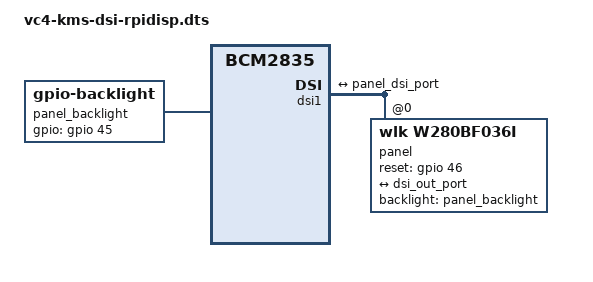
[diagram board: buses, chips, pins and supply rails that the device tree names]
/dts-v1/;
/plugin/;
/ {
	compatible = "brcm,bcm2835";  

	fragment@0 {
		target-path="/";
		__overlay__ {
			panel_backlight: panel_backlight {
				compatible = "gpio-backlight";
				gpios = <&gpio 45 0>;
				default-on;
			};
		};
	};
	
	fragment@1 {
		target = <&dsi1>;
		__overlay__{
			status = "okay";
			#address-cells = <1>;
			#size-cells = <0>;
			port {
				dsi_out_port:endpoint {
					remote-endpoint = <&panel_dsi_port>;
				};
			};

			panel:panel@0 {
				compatible    = "wlk,w280bf036i";
				status        = "okay";
				reg           = <0>;
				// reset-gpios   = <&gpio 44 0>;
				reset-gpios   = <&gpio 46 0>; // fix me
				backlight = <&panel_backlight>;
				rotation = <0>;
				port {
					panel_dsi_port: endpoint {
						remote-endpoint = <&dsi_out_port>;
					};
				};
			};
		};
	};
};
